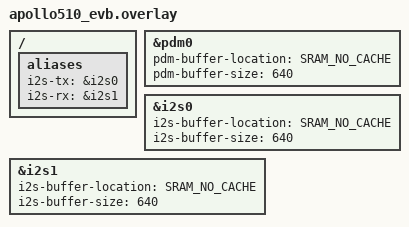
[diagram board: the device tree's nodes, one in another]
/ {
	aliases {
		i2s-tx = &i2s0;
		i2s-rx = &i2s1;
	};
};

dmic_dev: &pdm0 {
	pdm-buffer-location = "SRAM_NO_CACHE";
	pdm-buffer-size = <640>;
	status = "okay";
};

&i2s0 {
	i2s-buffer-location = "SRAM_NO_CACHE";
	i2s-buffer-size = <640>;
	status = "okay";
};

&i2s1 {
	i2s-buffer-location = "SRAM_NO_CACHE";
	i2s-buffer-size = <640>;
	status = "okay";
};
